# ATSAMRH71F20B register map
Vendor: Microchip Technology; Series: SAMRH71; File version: 0
CPU: CM7 r1p1, little endian, MPU, FPU, 3 interrupt priority bits
Registers are 32-bit, read-write, reset 0x0 unless marked. A register's access mark holds for its fields unless they carry their own. Offsets are from the block's base; [hi:lo] are bit positions.

## HSDRAMC — Hardened SDRAM Controller
Base 0x40082000; register names take the prefix HSDRAMC_
0x00 HSDRAMC_MR — Mode Register
  [2:0] MODE — SDRAMC Command Mode
    0=NORMAL (Normal mode. Any access to the SDRAM is decoded normally. To activate this mode, the command must be followed by a write to the SDRAM.); 1=NOP (The SDRAMC issues a NOP command when the SDRAM device is accessed regardless of the cycle. To activate this mode, the command must be followed by a write to the SDRAM.); 2=ALLBANKS_PRECHARGE (The SDRAMC issues an 'All Banks Precharge' command when the SDRAM device is accessed regardless of the cycle. To activate this mode, the command must be followed by a write to the SDRAM.); 3=LOAD_MODEREG (The SDRAMC issues a 'Load Mode Register' command when the SDRAM device is accessed regardless of the cycle. To activate this mode, the command must be followed by a write to the SDRAM.); 4=AUTO_REFRESH (The SDRAMC issues an 'Autorefresh' Command when the SDRAM device is accessed regardless of the cycle. Previously, an 'All Banks Precharge' command must be issued. To activate this mode, the command must be followed by a write to the SDRAM.); 5=EXT_LOAD_MODEREG (The SDRAMC issues an 'Extended Load Mode Register' command when the SDRAM device is accessed regardless of the cycle. To activate this mode, the 'Extended Load Mode Register' command must be followed by a write to the SDRAM. The write in the SDRAM must be done in the appropriate bank; most low-power SDRAM devices use the bank 1.)
0x04 HSDRAMC_TR — Refresh Timer Register
  [11:0] COUNT — SDRAMC Refresh Timer Count
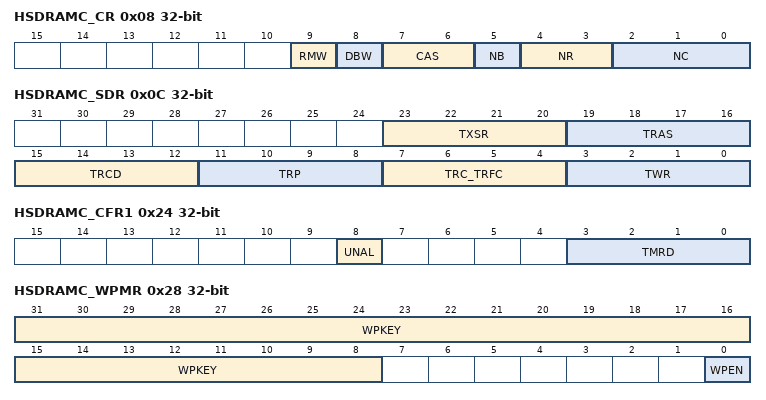
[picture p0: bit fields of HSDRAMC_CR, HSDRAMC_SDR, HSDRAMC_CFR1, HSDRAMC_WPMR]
0x08 HSDRAMC_CR — Configuration Register
  [9] RMW — Read Modify Write
  [8] DBW — Data Bus Width
  [7:6] CAS — CAS Latency
    1=LATENCY1 (1 cycle latency); 2=LATENCY2 (2 cycle latency); 3=LATENCY3 (3 cycle latency)
  [5] NB — Number of Banks
    0=BANK2 (2 banks); 1=BANK4 (4 banks)
  [4:3] NR — Number of Row Bits
    0=ROW11 (11 bits to define the row number, up to 2048 rows); 1=ROW12 (12 bits to define the row number, up to 4096 rows); 2=ROW13 (13 bits to define the row number, up to 8192 rows)
  [2:0] NC — Number of Column Bits
    0=COL8 (8 bits to define the column number, up to 256 columns); 1=COL9 (9 bits to define the column number, up to 512 columns); 2=COL10 (10 bits to define the column number, up to 1024 columns); 3=COL11 (11 bits to define the column number, up to 2048 columns); 4=COL12 (12 bits to define the column number, up to 4096 columns)
0x0C HSDRAMC_SDR — Setup Delay Register
  [23:20] TXSR — Exit Self-Refresh to Active Delay
  [19:16] TRAS — Active to Precharge Delay
  [15:12] TRCD — Row to Column Delay
  [11:8] TRP — Row Precharge Delay
  [7:4] TRC_TRFC — Row Cycle Delay and Row Refresh Cycle
  [3:0] TWR — Write Recovery Delay
0x14 HSDRAMC_IER wo — Interrupt Enable Register
  [0] RES — Refresh Error Interrupt Enable
0x18 HSDRAMC_IDR wo — Interrupt Disable Register
  [0] RES — Refresh Error Interrupt Disable
0x1C HSDRAMC_IMR ro — Interrupt Mask Register
  [0] RES — Refresh Error Interrupt Mask
0x20 HSDRAMC_ISR ro — Interrupt Status Register
  [0] RES — Refresh Error Status (cleared on read)
0x24 HSDRAMC_CFR1 — Configuration Register 1
  [8] UNAL — Support Unaligned Access
    0=UNSUPPORTED (Unaligned access is not supported.); 1=SUPPORTED (Unaligned access is supported.)
  [3:0] TMRD — Load Mode Register Command to Active or Refresh Command
0x28 HSDRAMC_WPMR — Write Protection Mode Register
  [31:8] WPKEY — Write Protection Key
    0x534452=PASSWD (Writing any other value in this field aborts the write operation of the WPEN bit.Always reads as 0.)
  [0] WPEN — Write Protection Enable
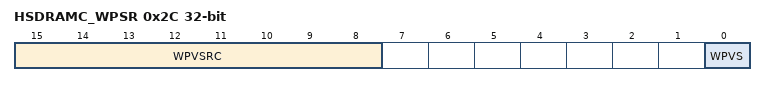
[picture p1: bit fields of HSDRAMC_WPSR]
0x2C HSDRAMC_WPSR ro — Write Protection Status Register
  [15:8] WPVSRC — Write Protection Violation Source
  [0] WPVS — Write Protection Violation Status
